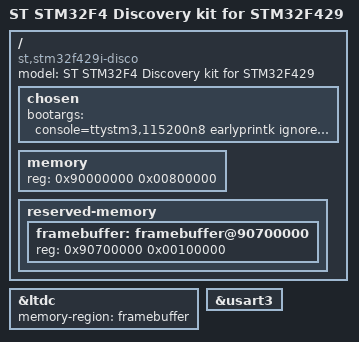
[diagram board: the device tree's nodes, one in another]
/*
 * Device tree for STM32F429I-DISCO
 */

/dts-v1/;
#include "stm32f429.dtsi"

/ {
	model = "ST STM32F4 Discovery kit for STM32F429";
	compatible = "st,stm32f429i-disco";

	chosen {
		bootargs = "console=ttystm3,115200n8 earlyprintk ignore_loglevel debug clk_ignore_unused ihash_entries=64 dhash_entries=64 uclinux.physaddr=0x08120000 root=/dev/mtdblock0 rdinit=/sbin/init"; /* lpj=714752 initcall_debug */
	};

	memory {
		reg = <0x90000000 0x00800000>;
	};

	reserved-memory {
		#address-cells = <1>;
		#size-cells = <1>;
		ranges;

		framebuffer: framebuffer@90700000 {
			reg = <0x90700000 0x00100000>;
		};
	};
};

&ltdc {
	memory-region = <&framebuffer>;
};

&usart3 {
	status = "okay";
};
